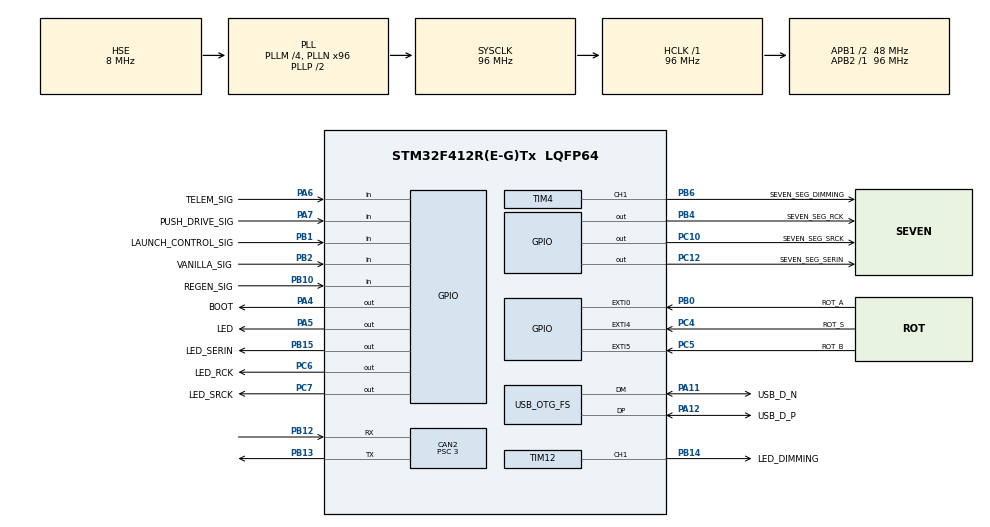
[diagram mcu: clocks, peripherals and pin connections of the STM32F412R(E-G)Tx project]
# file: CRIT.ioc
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CAN2.ABOM=ENABLE
CAN2.BS1=CAN_BS1_12TQ
CAN2.BS2=CAN_BS2_3TQ
CAN2.CalculateBaudRate=1000000
CAN2.CalculateTimeBit=1000
CAN2.CalculateTimeQuantum=62.5
CAN2.NART=ENABLE
CAN2.Prescaler=3
CAN2.RFLM=ENABLE
CAN2.SJW=CAN_SJW_3TQ
CAN2.TXFP=ENABLE
FREERTOS.Tasks01=Task1kHz,48,512,StartTask1kHz,Default,NULL,Static,Task1kHzBuffer,Task1kHzControlBlock;Task1Hz,32,512,RunTask1Hz,Default,NULL,Static,Task1HzBuffer,Task1HzControlBlock;Task100Hz,40,512,RunTask100Hz,Default,NULL,Static,Task100HzBuffer,Task100HzControlBlock;TaskCanRx,24,512,RunTaskCanRx,Default,NULL,Static,TaskCanRxBuffer,TaskCanRxControlBlock;TaskCanTx,24,512,RunTaskCanTx,Default,NULL,Static,TaskCanTxBuffer,TaskCanTxControlBlock;TaskChimera,40,512,RunTaskChimera,Default,NULL,Static,TaskChimeraBuffer,TaskChimeraControlBlock
FREERTOS.configENABLE_FPU=0
FREERTOS.configUSE_NEWLIB_REENTRANT=1
IWDG.Reload=LSI_FREQUENCY / IWDG_PRESCALER / IWDG_RESET_FREQUENCY
Mcu.Family=STM32F4
Mcu.Name=STM32F412R(E-G)Tx
Mcu.Package=LQFP64
Mcu.UserConstants=IWDG_RESET_FREQUENCY,5;SYS_TIMER_CLOCK,96000000;PWM_AUTO_RELOAD,4095;IWDG_PRESCALER,4;PWM_PRESCALER,650;LSI_FREQUENCY,32000
NVIC.CAN2_RX0_IRQn=true\:5\:0\:false\:false\:true\:true\:true\:true\:true
NVIC.CAN2_RX1_IRQn=true\:5\:0\:false\:false\:true\:true\:true\:true\:true
NVIC.CAN2_SCE_IRQn=true\:5\:0\:false\:false\:true\:true\:true\:true\:true
NVIC.CAN2_TX_IRQn=true\:5\:0\:false\:false\:true\:true\:true\:true\:true
NVIC.EXTI0_IRQn=true\:5\:0\:false\:false\:true\:true\:true\:true\:true
NVIC.EXTI4_IRQn=true\:5\:0\:false\:false\:true\:true\:true\:true\:true
NVIC.EXTI9_5_IRQn=true\:5\:0\:false\:false\:true\:true\:true\:true\:true
NVIC.FLASH_IRQn=true\:5\:0\:false\:false\:true\:true\:true\:true\:true
NVIC.FPU_IRQn=true\:5\:0\:false\:false\:true\:true\:true\:false\:true
NVIC.OTG_FS_IRQn=true\:5\:0\:false\:false\:true\:true\:false\:true\:true
NVIC.PVD_IRQn=true\:5\:0\:false\:false\:true\:true\:true\:true\:true
NVIC.PriorityGroup=NVIC_PRIORITYGROUP_4
NVIC.RCC_IRQn=true\:5\:0\:false\:false\:true\:true\:true\:false\:true
NVIC.TIM4_IRQn=true\:5\:0\:false\:false\:true\:true\:true\:true\:true
NVIC.TIM6_IRQn=true\:0\:0\:false\:false\:true\:false\:false\:true\:true
NVIC.TIM8_BRK_TIM12_IRQn=true\:5\:0\:false\:false\:true\:true\:true\:true\:true
NVIC.TimeBase=TIM6_IRQn
NVIC.TimeBaseIP=TIM6
PA11.GPIO_Label=USB_D_N
PA11.Mode=Device_Only
PA11.Signal=USB_OTG_FS_DM
PA12.GPIO_Label=USB_D_P
PA12.Mode=Device_Only
PA12.Signal=USB_OTG_FS_DP
PA13.GPIO_Label=SWDIO
PA13.Mode=Trace_Asynchronous_SW
PA13.Signal=SYS_JTMS-SWDIO
PA14.GPIO_Label=SWCLK
PA14.Mode=Trace_Asynchronous_SW
PA14.Signal=SYS_JTCK-SWCLK
PA4.GPIO_Label=BOOT
PA4.Signal=GPIO_Output
PA5.GPIO_Label=LED
PA5.Signal=GPIO_Output
PA6.GPIO_Label=TELEM_SIG
PA6.Signal=GPIO_Input
PA7.GPIO_Label=PUSH_DRIVE_SIG
PA7.Signal=GPIO_Input
PB0.GPIO_Label=ROT_A
PB0.GPIO_ModeDefaultEXTI=GPIO_MODE_IT_RISING_FALLING
PB0.GPIO_PuPd=GPIO_NOPULL
PB0.Signal=GPXTI0
PB1.GPIO_Label=LAUNCH_CONTROL_SIG
PB1.Signal=GPIO_Input
PB10.GPIO_Label=REGEN_SIG
PB10.Signal=GPIO_Input
PB12.Mode=CAN_Activate
PB12.Signal=CAN2_RX
PB13.Mode=CAN_Activate
PB13.Signal=CAN2_TX
PB14.GPIO_Label=LED_DIMMING
PB14.GPIO_Speed=GPIO_SPEED_FREQ_LOW
PB14.Signal=S_TIM12_CH1
PB15.GPIO_Label=LED_SERIN
PB15.GPIO_ModeDefaultOutputPP=GPIO_MODE_OUTPUT_OD
PB15.GPIO_PuPd=GPIO_NOPULL
PB15.Signal=GPIO_Output
PB2.GPIO_Label=VANILLA_SIG
PB2.Signal=GPIO_Input
PB3.GPIO_Label=SWO
PB3.Mode=Trace_Asynchronous_SW
PB3.Signal=SYS_JTDO-SWO
PB4.GPIO_Label=SEVEN_SEG_RCK
PB4.GPIO_ModeDefaultOutputPP=GPIO_MODE_OUTPUT_OD
PB4.GPIO_PuPd=GPIO_NOPULL
PB4.Signal=GPIO_Output
PB6.GPIO_Label=SEVEN_SEG_DIMMING
PB6.GPIO_Speed=GPIO_SPEED_FREQ_LOW
PB6.Signal=S_TIM4_CH1
PC10.GPIO_Label=SEVEN_SEG_SRCK
PC10.GPIO_ModeDefaultOutputPP=GPIO_MODE_OUTPUT_OD
PC10.GPIO_PuPd=GPIO_NOPULL
PC10.Signal=GPIO_Output
PC12.GPIO_Label=SEVEN_SEG_SERIN
PC12.GPIO_ModeDefaultOutputPP=GPIO_MODE_OUTPUT_OD
PC12.GPIO_PuPd=GPIO_NOPULL
PC12.Signal=GPIO_Output
PC4.GPIO_Label=ROT_S
PC4.Signal=GPXTI4
PC5.GPIO_Label=ROT_B
PC5.GPIO_ModeDefaultEXTI=GPIO_MODE_IT_RISING_FALLING
PC5.Signal=GPXTI5
PC6.GPIO_Label=LED_RCK
PC6.GPIO_ModeDefaultOutputPP=GPIO_MODE_OUTPUT_OD
PC6.GPIO_PuPd=GPIO_NOPULL
PC6.Signal=GPIO_Output
PC7.GPIO_Label=LED_SRCK
PC7.GPIO_ModeDefaultOutputPP=GPIO_MODE_OUTPUT_OD
PC7.GPIO_PuPd=GPIO_NOPULL
PC7.Signal=GPIO_Output
PH0\ -\ OSC_IN.Mode=HSE-External-Oscillator
PH0\ -\ OSC_IN.Signal=RCC_OSC_IN
PH1\ -\ OSC_OUT.Mode=HSE-External-Oscillator
PH1\ -\ OSC_OUT.Signal=RCC_OSC_OUT
ProjectManager.HeapSize=0x000
ProjectManager.StackSize=0x400
ProjectManager.TargetToolchain=STM32CubeIDE
RCC.AHBFreq_Value=96000000
RCC.APB1CLKDivider=RCC_HCLK_DIV2
RCC.APB1Freq_Value=48000000
RCC.APB1TimFreq_Value=96000000
RCC.APB2Freq_Value=96000000
RCC.APB2TimFreq_Value=96000000
RCC.CortexFreq_Value=96000000
RCC.HCLKFreq_Value=96000000
RCC.HSE_VALUE=8000000
RCC.PLLI2SM=2
RCC.PLLI2SN=50
RCC.PLLM=4
RCC.PLLN=96
RCC.PLLQ=4
RCC.RCC_MCO1Source=RCC_MCO1SOURCE_HSE
RCC.RCC_MCO2Source=RCC_MCO2SOURCE_HSE
RCC.SYSCLKFreq_VALUE=96000000
RCC.SYSCLKSource=RCC_SYSCLKSOURCE_PLLCLK
RCC.USBFreq_Value=48000000
RCC.VCOOutputFreq_Value=192000000
SH.S_TIM12_CH1.0=TIM12_CH1,PWM Generation1 CH1
SH.S_TIM4_CH1.0=TIM4_CH1,PWM Generation1 CH1
TIM12.AutoReloadPreload=TIM_AUTORELOAD_PRELOAD_ENABLE
TIM12.Channel-PWM\ Generation1\ CH1=TIM_CHANNEL_1
TIM12.OC1Preload_PWM=ENABLE
TIM12.OCPolarity_1=TIM_OCPOLARITY_LOW
TIM12.Period=PWM_AUTO_RELOAD
TIM12.Prescaler=PWM_PRESCALER
TIM4.AutoReloadPreload=TIM_AUTORELOAD_PRELOAD_ENABLE
TIM4.Channel-PWM\ Generation1\ CH1=TIM_CHANNEL_1
TIM4.OCPolarity_1=TIM_OCPOLARITY_LOW
TIM4.Period=PWM_AUTO_RELOAD
TIM4.Prescaler=PWM_PRESCALER
USB_DEVICE.CLASS_NAME_FS=CDC
USB_DEVICE.MANUFACTURER_STRING=ubc_formula_electric
USB_DEVICE.PRODUCT_STRING_CDC_FS=crit
USB_DEVICE.VirtualMode=Cdc
USB_DEVICE.VirtualModeFS=Cdc_FS
USB_OTG_FS.VirtualMode=Device_Only
VP_FREERTOS_VS_CMSIS_V2.Mode=CMSIS_V2
VP_IWDG_VS_IWDG.Mode=IWDG_Activate
VP_SYS_VS_tim6.Mode=TIM6
VP_USB_DEVICE_VS_USB_DEVICE_CDC_FS.Mode=CDC_FS
board=custom

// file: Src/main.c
/* USER CODE BEGIN Header */
//Cpp integration requirement
#ifdef __cplusplus
extern "C" {
#endif
void RTOSTHREAD_CreateTasks(void);
#ifdef __cplusplus
}
#endif

/**
 ******************************************************************************
 * @file           : main.c
 * @brief          : Main program body
 ******************************************************************************
 * @attention
 *
 * Copyright (c) 2025 STMicroelectronics.
 * All rights reserved.
 *
 * This software is licensed under terms that can be found in the LICENSE file
 * in the root directory of this software component.
 * If no LICENSE file comes with this software, it is provided AS-IS.
 *
 ******************************************************************************
 */
/* USER CODE END Header */
#include "main.h"
#include "usb_device.h"

/* USER CODE BEGIN Includes */
#include "tasks.h"
/* USER CODE END Includes */

typedef StaticTask_t osStaticThreadDef_t;

CAN_HandleTypeDef hcan2;

IWDG_HandleTypeDef hiwdg;

TIM_HandleTypeDef htim4;
TIM_HandleTypeDef htim12;

void        SystemClock_Config(void);
static void MX_GPIO_Init(void);
static void MX_CAN2_Init(void);
static void MX_TIM4_Init(void);
static void MX_TIM12_Init(void);
static void MX_IWDG_Init(void);
void        StartTask1kHz(void *argument);
void        RunTask1Hz(void *argument);
void        RunTask100Hz(void *argument);
void        RunTaskCanRx(void *argument);
void        RunTaskCanTx(void *argument);
void        RunTaskChimera(void *argument);

int main(void)
{
    /* USER CODE BEGIN 1 */
    tasks_preInit();
    /* USER CODE END 1 */

    /* MCU Configuration--------------------------------------------------------*/

    /* Reset of all peripherals, Initializes the Flash interface and the Systick. */
    HAL_Init();

    /* Configure the system clock */
    SystemClock_Config();

    /* Initialize all configured peripherals */
    MX_GPIO_Init();
    MX_CAN2_Init();
    MX_TIM4_Init();
    MX_TIM12_Init();
    MX_IWDG_Init();

    /* Init scheduler */
    osKernelInitialize();

    /* USER CODE BEGIN RTOS_QUEUES */
    tasks_init();
    /* USER CODE END RTOS_QUEUES */

    /* Create the thread(s) */
    RTOSTHREAD_CreateTasks();   // creates all tasks inshallah

    /* Start scheduler */
    osKernelStart();

    /* We should never get here as control is now taken by the scheduler */

    /* Infinite loop */
    while (1)
    {

    }
}

void SystemClock_Config(void)
{
    RCC_OscInitTypeDef RCC_OscInitStruct = { 0 };
    RCC_ClkInitTypeDef RCC_ClkInitStruct = { 0 };

    /** Configure the main internal regulator output voltage
     */
    __HAL_RCC_PWR_CLK_ENABLE();
    __HAL_PWR_VOLTAGESCALING_CONFIG(PWR_REGULATOR_VOLTAGE_SCALE1);

    /** Initializes the RCC Oscillators according to the specified parameters
     * in the RCC_OscInitTypeDef structure.
     */
    RCC_OscInitStruct.OscillatorType = RCC_OSCILLATORTYPE_LSI | RCC_OSCILLATORTYPE_HSE;
    RCC_OscInitStruct.HSEState       = RCC_HSE_ON;
    RCC_OscInitStruct.LSIState       = RCC_LSI_ON;
    RCC_OscInitStruct.PLL.PLLState   = RCC_PLL_ON;
    RCC_OscInitStruct.PLL.PLLSource  = RCC_PLLSOURCE_HSE;
    RCC_OscInitStruct.PLL.PLLM       = 4;
    RCC_OscInitStruct.PLL.PLLN       = 96;
    RCC_OscInitStruct.PLL.PLLP       = RCC_PLLP_DIV2;
    RCC_OscInitStruct.PLL.PLLQ       = 4;
    RCC_OscInitStruct.PLL.PLLR       = 2;
    if (HAL_RCC_OscConfig(&RCC_OscInitStruct) != HAL_OK)
    {
        Error_Handler();
    }

    /** Initializes the CPU, AHB and APB buses clocks
     */
    RCC_ClkInitStruct.ClockType = RCC_CLOCKTYPE_HCLK | RCC_CLOCKTYPE_SYSCLK | RCC_CLOCKTYPE_PCLK1 | RCC_CLOCKTYPE_PCLK2;
    RCC_ClkInitStruct.SYSCLKSource   = RCC_SYSCLKSOURCE_PLLCLK;
    RCC_ClkInitStruct.AHBCLKDivider  = RCC_SYSCLK_DIV1;
    RCC_ClkInitStruct.APB1CLKDivider = RCC_HCLK_DIV2;
    RCC_ClkInitStruct.APB2CLKDivider = RCC_HCLK_DIV1;

    if (HAL_RCC_ClockConfig(&RCC_ClkInitStruct, FLASH_LATENCY_3) != HAL_OK)
    {
        Error_Handler();
    }
}

static void MX_CAN2_Init(void)
{

    hcan2.Instance                  = CAN2;
    hcan2.Init.Prescaler            = 3;
    hcan2.Init.Mode                 = CAN_MODE_NORMAL;
    hcan2.Init.SyncJumpWidth        = CAN_SJW_3TQ;
    hcan2.Init.TimeSeg1             = CAN_BS1_12TQ;
    hcan2.Init.TimeSeg2             = CAN_BS2_3TQ;
    hcan2.Init.TimeTriggeredMode    = DISABLE;
    hcan2.Init.AutoBusOff           = ENABLE;
    hcan2.Init.AutoWakeUp           = DISABLE;
    hcan2.Init.AutoRetransmission   = ENABLE;
    hcan2.Init.ReceiveFifoLocked    = ENABLE;
    hcan2.Init.TransmitFifoPriority = ENABLE;
    if (HAL_CAN_Init(&hcan2) != HAL_OK)
    {
        Error_Handler();
    }
}

static void MX_IWDG_Init(void)
{
    /* USER CODE BEGIN IWDG_Init 0 */
#ifndef WATCHDOG_DISABLED
    /* USER CODE END IWDG_Init 0 */

    hiwdg.Instance       = IWDG;
    hiwdg.Init.Prescaler = IWDG_PRESCALER_4;
    hiwdg.Init.Reload    = LSI_FREQUENCY / IWDG_PRESCALER / IWDG_RESET_FREQUENCY;
    if (HAL_IWDG_Init(&hiwdg) != HAL_OK)
    {
        Error_Handler();
    }
    /* USER CODE BEGIN IWDG_Init 2 */
#endif
    /* USER CODE END IWDG_Init 2 */
}

static void MX_TIM4_Init(void)
{

    TIM_MasterConfigTypeDef sMasterConfig = { 0 };
    TIM_OC_InitTypeDef      sConfigOC     = { 0 };

    htim4.Instance               = TIM4;
    htim4.Init.Prescaler         = PWM_PRESCALER;
    htim4.Init.CounterMode       = TIM_COUNTERMODE_UP;
    htim4.Init.Period            = PWM_AUTO_RELOAD;
    htim4.Init.ClockDivision     = TIM_CLOCKDIVISION_DIV1;
    htim4.Init.AutoReloadPreload = TIM_AUTORELOAD_PRELOAD_ENABLE;
    if (HAL_TIM_PWM_Init(&htim4) != HAL_OK)
    {
        Error_Handler();
    }
    sMasterConfig.MasterOutputTrigger = TIM_TRGO_RESET;
    sMasterConfig.MasterSlaveMode     = TIM_MASTERSLAVEMODE_DISABLE;
    if (HAL_TIMEx_MasterConfigSynchronization(&htim4, &sMasterConfig) != HAL_OK)
    {
        Error_Handler();
    }
    sConfigOC.OCMode     = TIM_OCMODE_PWM1;
    sConfigOC.Pulse      = 0;
    sConfigOC.OCPolarity = TIM_OCPOLARITY_LOW;
    sConfigOC.OCFastMode = TIM_OCFAST_DISABLE;
    if (HAL_TIM_PWM_ConfigChannel(&htim4, &sConfigOC, TIM_CHANNEL_1) != HAL_OK)
    {
        Error_Handler();
    }
    HAL_TIM_MspPostInit(&htim4);
}

static void MX_TIM12_Init(void)
{

    TIM_OC_InitTypeDef sConfigOC = { 0 };

    htim12.Instance               = TIM12;
    htim12.Init.Prescaler         = PWM_PRESCALER;
    htim12.Init.CounterMode       = TIM_COUNTERMODE_UP;
    htim12.Init.Period            = PWM_AUTO_RELOAD;
    htim12.Init.ClockDivision     = TIM_CLOCKDIVISION_DIV1;
    htim12.Init.AutoReloadPreload = TIM_AUTORELOAD_PRELOAD_ENABLE;
    if (HAL_TIM_PWM_Init(&htim12) != HAL_OK)
    {
        Error_Handler();
    }
    sConfigOC.OCMode     = TIM_OCMODE_PWM1;
    sConfigOC.Pulse      = 0;
    sConfigOC.OCPolarity = TIM_OCPOLARITY_LOW;
    sConfigOC.OCFastMode = TIM_OCFAST_DISABLE;
    if (HAL_TIM_PWM_ConfigChannel(&htim12, &sConfigOC, TIM_CHANNEL_1) != HAL_OK)
    {
        Error_Handler();
    }
    HAL_TIM_MspPostInit(&htim12);
}

static void MX_GPIO_Init(void)
{
    GPIO_InitTypeDef GPIO_InitStruct = { 0 };

    /* GPIO Ports Clock Enable */
    __HAL_RCC_GPIOH_CLK_ENABLE();
    __HAL_RCC_GPIOA_CLK_ENABLE();
    __HAL_RCC_GPIOC_CLK_ENABLE();
    __HAL_RCC_GPIOB_CLK_ENABLE();

    /*Configure GPIO pin Output Level */
    HAL_GPIO_WritePin(GPIOA, BOOT_Pin | LED_Pin, GPIO_PIN_RESET);

    /*Configure GPIO pin Output Level */
    HAL_GPIO_WritePin(GPIOB, LED_SERIN_Pin | SEVEN_SEG_RCK_Pin, GPIO_PIN_RESET);

    /*Configure GPIO pin Output Level */
    HAL_GPIO_WritePin(GPIOC, LED_RCK_Pin | LED_SRCK_Pin | SEVEN_SEG_SRCK_Pin | SEVEN_SEG_SERIN_Pin, GPIO_PIN_RESET);

    /*Configure GPIO pins : BOOT_Pin LED_Pin */
    GPIO_InitStruct.Pin   = BOOT_Pin | LED_Pin;
    GPIO_InitStruct.Mode  = GPIO_MODE_OUTPUT_PP;
    GPIO_InitStruct.Pull  = GPIO_NOPULL;
    GPIO_InitStruct.Speed = GPIO_SPEED_FREQ_LOW;
    HAL_GPIO_Init(GPIOA, &GPIO_InitStruct);

    /*Configure GPIO pins : TELEM_SIG_Pin PUSH_DRIVE_SIG_Pin */
    GPIO_InitStruct.Pin  = TELEM_SIG_Pin | PUSH_DRIVE_SIG_Pin;
    GPIO_InitStruct.Mode = GPIO_MODE_INPUT;
    GPIO_InitStruct.Pull = GPIO_NOPULL;
    HAL_GPIO_Init(GPIOA, &GPIO_InitStruct);

    /*Configure GPIO pin : ROT_S_Pin */
    GPIO_InitStruct.Pin  = ROT_S_Pin;
    GPIO_InitStruct.Mode = GPIO_MODE_IT_RISING;
    GPIO_InitStruct.Pull = GPIO_NOPULL;
    HAL_GPIO_Init(ROT_S_GPIO_Port, &GPIO_InitStruct);

    /*Configure GPIO pin : ROT_B_Pin */
    GPIO_InitStruct.Pin  = ROT_B_Pin;
    GPIO_InitStruct.Mode = GPIO_MODE_IT_RISING_FALLING;
    GPIO_InitStruct.Pull = GPIO_NOPULL;
    HAL_GPIO_Init(ROT_B_GPIO_Port, &GPIO_InitStruct);

    /*Configure GPIO pin : ROT_A_Pin */
    GPIO_InitStruct.Pin  = ROT_A_Pin;
    GPIO_InitStruct.Mode = GPIO_MODE_IT_RISING_FALLING;
    GPIO_InitStruct.Pull = GPIO_NOPULL;
    HAL_GPIO_Init(ROT_A_GPIO_Port, &GPIO_InitStruct);

    /*Configure GPIO pins : LAUNCH_CONTROL_SIG_Pin VANILLA_SIG_Pin REGEN_SIG_Pin */
    GPIO_InitStruct.Pin  = LAUNCH_CONTROL_SIG_Pin | VANILLA_SIG_Pin | REGEN_SIG_Pin;
    GPIO_InitStruct.Mode = GPIO_MODE_INPUT;
    GPIO_InitStruct.Pull = GPIO_NOPULL;
    HAL_GPIO_Init(GPIOB, &GPIO_InitStruct);

    /*Configure GPIO pins : LED_SERIN_Pin SEVEN_SEG_RCK_Pin */
    GPIO_InitStruct.Pin   = LED_SERIN_Pin | SEVEN_SEG_RCK_Pin;
    GPIO_InitStruct.Mode  = GPIO_MODE_OUTPUT_OD;
    GPIO_InitStruct.Pull  = GPIO_NOPULL;
    GPIO_InitStruct.Speed = GPIO_SPEED_FREQ_LOW;
    HAL_GPIO_Init(GPIOB, &GPIO_InitStruct);

    /*Configure GPIO pins : LED_RCK_Pin LED_SRCK_Pin SEVEN_SEG_SRCK_Pin SEVEN_SEG_SERIN_Pin */
    GPIO_InitStruct.Pin   = LED_RCK_Pin | LED_SRCK_Pin | SEVEN_SEG_SRCK_Pin | SEVEN_SEG_SERIN_Pin;
    GPIO_InitStruct.Mode  = GPIO_MODE_OUTPUT_OD;
    GPIO_InitStruct.Pull  = GPIO_NOPULL;
    GPIO_InitStruct.Speed = GPIO_SPEED_FREQ_LOW;
    HAL_GPIO_Init(GPIOC, &GPIO_InitStruct);

    /* EXTI interrupt init*/
    HAL_NVIC_SetPriority(EXTI0_IRQn, 5, 0);
    HAL_NVIC_EnableIRQ(EXTI0_IRQn);

    HAL_NVIC_SetPriority(EXTI4_IRQn, 5, 0);
    HAL_NVIC_EnableIRQ(EXTI4_IRQn);

    HAL_NVIC_SetPriority(EXTI9_5_IRQn, 5, 0);
    HAL_NVIC_EnableIRQ(EXTI9_5_IRQn);

}

void StartTask1kHz(void *argument)
{
    /* init code for USB_DEVICE */
    MX_USB_DEVICE_Init();
    /* USER CODE BEGIN 5 */
    tasks_run1kHz();
    /* USER CODE END 5 */
}

void RunTask1Hz(void *argument)
{
    /* USER CODE BEGIN RunTask1Hz */
    tasks_run1Hz();
    /* USER CODE END RunTask1Hz */
}

void RunTask100Hz(void *argument)
{
    /* USER CODE BEGIN RunTask100Hz */
    tasks_run100Hz();
    /* USER CODE END RunTask100Hz */
}

void RunTaskCanRx(void *argument)
{
    /* USER CODE BEGIN RunTaskCanRx */
    tasks_runCanRx();
    /* USER CODE END RunTaskCanRx */
}

void RunTaskCanTx(void *argument)
{
    /* USER CODE BEGIN RunTaskCanTx */
    tasks_runCanTx();
    /* USER CODE END RunTaskCanTx */
}

void RunTaskChimera(void *argument)
{
    /* USER CODE BEGIN RunTaskChimera */
    /* Infinite loop */
    tasks_runChimera();
    /* USER CODE END RunTaskChimera */
}

void HAL_TIM_PeriodElapsedCallback(TIM_HandleTypeDef *htim)
{
    if (htim->Instance == TIM6)
    {
        HAL_IncTick();
    }
}

void Error_Handler(void)
{
    __disable_irq();
    while (1)
    {
    }
}
